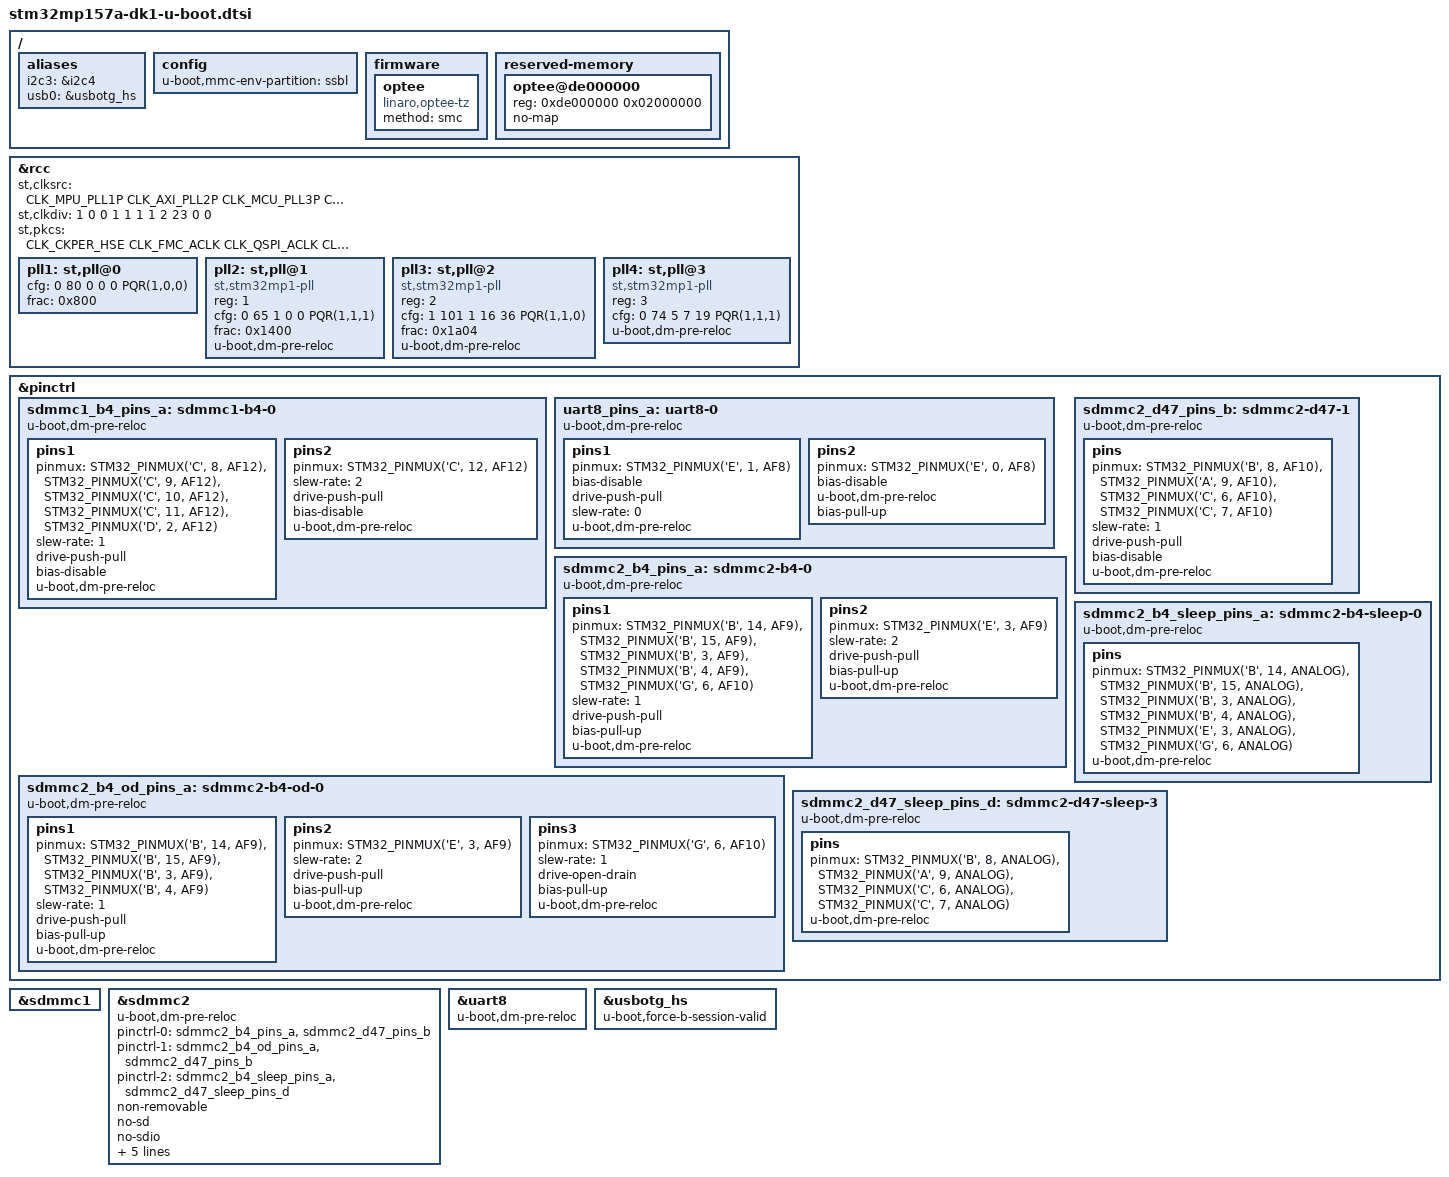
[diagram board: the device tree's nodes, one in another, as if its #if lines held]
// SPDX-License-Identifier: GPL-2.0+ OR BSD-3-Clause
/*
 * Copyright : STMicroelectronics 2018
 */

#include <dt-bindings/clock/stm32mp1-clksrc.h>
#include "stm32mp15-u-boot.dtsi"
#include "stm32mp15-ddr3-1x4Gb-1066-binG.dtsi"

/ {
	aliases {
		i2c3 = &i2c4;
		usb0 = &usbotg_hs;
	};

#if defined(CONFIG_STM32MP15x_STM32IMAGE) || defined(CONFIG_SPL)
	config {
		u-boot,mmc-env-partition = "ssbl";
	};
#endif

#ifdef CONFIG_STM32MP15x_STM32IMAGE
	/* only needed for boot with TF-A, witout FIP support */
	firmware {
		optee {
			compatible = "linaro,optee-tz";
			method = "smc";
		};
	};

	reserved-memory {
		u-boot,dm-spl;

		optee@de000000 {
			reg = <0xde000000 0x02000000>;
			no-map;
			u-boot,dm-spl;
		};
	};
#endif

};

&rcc {
	st,clksrc = <
		CLK_MPU_PLL1P
		CLK_AXI_PLL2P
		CLK_MCU_PLL3P
		CLK_PLL12_HSE
		CLK_PLL3_HSE
		CLK_PLL4_HSE
		CLK_RTC_LSE
		CLK_MCO1_DISABLED
		CLK_MCO2_DISABLED
	>;

	st,clkdiv = <
		1 /*MPU*/
		0 /*AXI*/
		0 /*MCU*/
		1 /*APB1*/
		1 /*APB2*/
		1 /*APB3*/
		1 /*APB4*/
		2 /*APB5*/
		23 /*RTC*/
		0 /*MCO1*/
		0 /*MCO2*/
	>;

	st,pkcs = <
		CLK_CKPER_HSE
		CLK_FMC_ACLK
		CLK_QSPI_ACLK
		CLK_ETH_DISABLED
		CLK_SDMMC12_PLL4P
		CLK_DSI_DSIPLL
		CLK_STGEN_HSE
		CLK_USBPHY_PLL4R
		CLK_SPI2S1_PLL3Q
		CLK_SPI2S23_PLL3Q
		CLK_SPI45_HSI
		CLK_SPI6_HSI
		CLK_I2C46_HSI
		CLK_SDMMC3_PLL4P
		CLK_USBO_USBPHY
		CLK_ADC_CKPER
		CLK_CEC_LSE
		CLK_I2C12_HSI
		CLK_I2C35_HSI
		CLK_UART1_HSI
		CLK_UART24_HSI
		CLK_UART35_HSI
		CLK_UART6_HSI
		CLK_UART78_HSI
		CLK_SPDIF_PLL4P
		CLK_FDCAN_PLL4R
		CLK_SAI1_PLL3Q
		CLK_SAI2_PLL3Q
		CLK_SAI3_PLL3Q
		CLK_SAI4_PLL3Q
		CLK_RNG1_LSI
		CLK_RNG2_LSI
		CLK_LPTIM1_PCLK1
		CLK_LPTIM23_PCLK3
		CLK_LPTIM45_LSE
	>;
	
	pll1: st,pll@0 {
		cfg = < 0 80 0 0 0 PQR(1,0,0) >;
		frac = < 0x800 >;
	};

	/* VCO = 1066.0 MHz => P = 266 (AXI), Q = 533 (GPU), R = 533 (DDR) */
	pll2: st,pll@1 {
		compatible = "st,stm32mp1-pll";
		reg = <1>;
		cfg = < 0 65 1 0 0 PQR(1,1,1) >;
		frac = < 0x1400 >;
		u-boot,dm-pre-reloc;
	};

	/* VCO = 417.8 MHz => P = 209, Q = 24, R = 11 */
	pll3: st,pll@2 {
		compatible = "st,stm32mp1-pll";
		reg = <2>;
		cfg = < 1 101 1 16 36 PQR(1,1,0) >;
		frac = < 0x1a04 >;
		u-boot,dm-pre-reloc;
	};

	/* VCO = 594.0 MHz => P = 99, Q = 74, R = 74 */
	pll4: st,pll@3 {
		compatible = "st,stm32mp1-pll";
		reg = <3>;
		cfg = < 0 74 5 7 19 PQR(1,1,1) >;
		u-boot,dm-pre-reloc;
	};
};

&pinctrl {
	sdmmc1_b4_pins_a: sdmmc1-b4-0 {
		pins1 {
			pinmux = <STM32_PINMUX('C', 8, AF12)>, /* SDMMC1_D0 */
				 <STM32_PINMUX('C', 9, AF12)>, /* SDMMC1_D1 */
				 <STM32_PINMUX('C', 10, AF12)>, /* SDMMC1_D2 */
				 <STM32_PINMUX('C', 11, AF12)>, /* SDMMC1_D3 */
				 <STM32_PINMUX('D', 2, AF12)>; /* SDMMC1_CMD */
			slew-rate = <1>;
			drive-push-pull;
			bias-disable;
		};
		pins2 {
			pinmux = <STM32_PINMUX('C', 12, AF12)>; /* SDMMC1_CK */
			slew-rate = <2>;
			drive-push-pull;
			bias-disable;
		};
	};
	
	uart8_pins_a: uart8-0 {
		pins1 {
			pinmux = <STM32_PINMUX('E', 1, AF8)>; /* UART8_TX */
			bias-disable;
			drive-push-pull;
			slew-rate = <0>;
		};
		pins2 {
			pinmux = <STM32_PINMUX('E', 0, AF8)>; /* UART8_RX */
			bias-disable;
		};
	};
	
	sdmmc2_b4_pins_a: sdmmc2-b4-0 {
		pins1 {
			pinmux = <STM32_PINMUX('B', 14, AF9)>, /* SDMMC2_D0 */
				 <STM32_PINMUX('B', 15, AF9)>, /* SDMMC2_D1 */
				 <STM32_PINMUX('B', 3, AF9)>, /* SDMMC2_D2 */
				 <STM32_PINMUX('B', 4, AF9)>, /* SDMMC2_D3 */
				 <STM32_PINMUX('G', 6, AF10)>; /* SDMMC2_CMD */
			slew-rate = <1>;
			drive-push-pull;
			bias-pull-up;
		};
		pins2 {
			pinmux = <STM32_PINMUX('E', 3, AF9)>; /* SDMMC2_CK */
			slew-rate = <2>;
			drive-push-pull;
			bias-pull-up;
		};
	};
	
	sdmmc2_b4_od_pins_a: sdmmc2-b4-od-0 {
		pins1 {
			pinmux = <STM32_PINMUX('B', 14, AF9)>, /* SDMMC2_D0 */
				 <STM32_PINMUX('B', 15, AF9)>, /* SDMMC2_D1 */
				 <STM32_PINMUX('B', 3, AF9)>, /* SDMMC2_D2 */
				 <STM32_PINMUX('B', 4, AF9)>; /* SDMMC2_D3 */
			slew-rate = <1>;
			drive-push-pull;
			bias-pull-up;
		};
		pins2 {
			pinmux = <STM32_PINMUX('E', 3, AF9)>; /* SDMMC2_CK */
			slew-rate = <2>;
			drive-push-pull;
			bias-pull-up;
		};
		pins3 {
			pinmux = <STM32_PINMUX('G', 6, AF10)>; /* SDMMC2_CMD */
			slew-rate = <1>;
			drive-open-drain;
			bias-pull-up;
		};
	};
	
	sdmmc2_d47_pins_b: sdmmc2-d47-1 {
		pins {
			pinmux = <STM32_PINMUX('B', 8, AF10)>,  /* SDMMC2_D4 */
				 <STM32_PINMUX('A', 9, AF10)>, /* SDMMC2_D5 */
				 <STM32_PINMUX('C', 6, AF10)>, /* SDMMC2_D6 */
				 <STM32_PINMUX('C', 7, AF10)>; /* SDMMC2_D7 */
			slew-rate = <1>;
			drive-push-pull;
			bias-disable;
		};
	};
		
	
	sdmmc2_b4_sleep_pins_a: sdmmc2-b4-sleep-0 {
		pins {
			pinmux = <STM32_PINMUX('B', 14, ANALOG)>, /* SDMMC2_D0 */
				 <STM32_PINMUX('B', 15, ANALOG)>, /* SDMMC2_D1 */
				 <STM32_PINMUX('B', 3, ANALOG)>, /* SDMMC2_D2 */
				 <STM32_PINMUX('B', 4, ANALOG)>, /* SDMMC2_D3 */
				 <STM32_PINMUX('E', 3, ANALOG)>, /* SDMMC2_CK */
				 <STM32_PINMUX('G', 6, ANALOG)>; /* SDMMC2_CMD */
		};
	};
	
	sdmmc2_d47_sleep_pins_d: sdmmc2-d47-sleep-3 {
		pins {
			pinmux = <STM32_PINMUX('B', 8, ANALOG)>, /* SDMMC2_D4 */
				 <STM32_PINMUX('A', 9, ANALOG)>, /* SDMMC2_D5 */
				 <STM32_PINMUX('C', 6, ANALOG)>, /* SDMMC2_D6 */
				 <STM32_PINMUX('C', 7, ANALOG)>; /* SDMMC2_D7 */
		};
	};
};
&sdmmc1 {
	u-boot,dm-spl;
};

&sdmmc2 {
	u-boot,dm-pre-reloc;
	pinctrl-names = "default", "opendrain", "sleep";
	pinctrl-0 = <&sdmmc2_b4_pins_a &sdmmc2_d47_pins_b>;
	pinctrl-1 = <&sdmmc2_b4_od_pins_a &sdmmc2_d47_pins_b>;
	pinctrl-2 = <&sdmmc2_b4_sleep_pins_a &sdmmc2_d47_sleep_pins_d>;
	non-removable;
	no-sd;
	no-sdio;
	st,neg-edge;
	bus-width = <8>;
	vmmc-supply = <&v3v3>;
	vqmmc-supply = <&vdd>;
	mmc-ddr-3_3v;
	status = "okay";
};



&sdmmc1_b4_pins_a {
	u-boot,dm-pre-reloc;
	pins1 {
		u-boot,dm-pre-reloc;
	};
	pins2 {
		u-boot,dm-pre-reloc;
	};
};


&sdmmc2_b4_pins_a {
	u-boot,dm-pre-reloc;
	pins1 {
		u-boot,dm-pre-reloc;
	};
	pins2 {
		u-boot,dm-pre-reloc;
	};
};

&sdmmc2_b4_od_pins_a {
	u-boot,dm-pre-reloc;
	pins1 {
		u-boot,dm-pre-reloc;
	};
	pins2 {
		u-boot,dm-pre-reloc;
	};
	pins3 {
		u-boot,dm-pre-reloc;
	};
};

&sdmmc2_d47_pins_b {
	u-boot,dm-pre-reloc;
	pins {
		u-boot,dm-pre-reloc;
	};
	
};

&sdmmc2_b4_sleep_pins_a {
	u-boot,dm-pre-reloc;
	pins {
		u-boot,dm-pre-reloc;
	};
	
};

&sdmmc2_d47_sleep_pins_d {
	u-boot,dm-pre-reloc;
	pins {
		u-boot,dm-pre-reloc;
	};
	
};

&uart8 {
	u-boot,dm-pre-reloc;
};

&uart8_pins_a {
	u-boot,dm-pre-reloc;
	pins1 {
		u-boot,dm-pre-reloc;
	};
	pins2 {
		u-boot,dm-pre-reloc;
		/* pull-up on rx to avoid floating level */
		bias-pull-up;
	};
};


&usbotg_hs {
	u-boot,force-b-session-valid;
};
